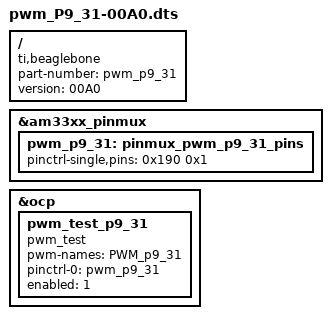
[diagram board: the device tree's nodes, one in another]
/dts-v1/;
/plugin/;

/ {
	compatible = "ti,beaglebone", "ti,beaglebone-black";

	/* identification */
	part-number = "pwm_p9_31";
	version = "00A0";

	fragment@0 {
		target = <&am33xx_pinmux>;
		__overlay__ {
			pwm_p9_31: pinmux_pwm_p9_31_pins {
				pinctrl-single,pins = <0x190 0x1>;
			};
		};
	};

	fragment@1 {
		target = <&ocp>;
		__overlay__ {
			pwm_test_p9_31 {
				compatible	= "pwm_test";
				pwm-names 	= "PWM_p9_31";
				pinctrl-names	= "default";
				pinctrl-0	= <&pwm_p9_31>;
				enabled		= <1>;
				status 		= "okay";
			};
		};
	};

};
